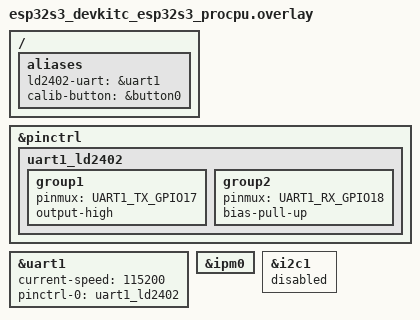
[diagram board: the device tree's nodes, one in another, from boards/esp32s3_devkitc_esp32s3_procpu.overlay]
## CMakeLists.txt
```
# PRO_CPU (core 0) image = sensor core. Sysbuild adds the APP_CPU image (remote/).
cmake_minimum_required(VERSION 3.20.0)

find_package(Zephyr REQUIRED HINTS $ENV{ZEPHYR_BASE})
project(ld2402_sensor_procpu)

target_include_directories(app PRIVATE common src)
target_sources(app PRIVATE
	src/sensor_main.c
	src/ld2402.c
	src/radar_trend.c
	src/radar_filter.c
	common/radar_link_ipm.c
)
```

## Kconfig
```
# Sensor-core application options.
mainmenu "LD2402 sensor core"

config LD2402_RX_POLLING
	bool "Poll the LD2402 UART instead of using RX interrupts"
	help
	  Fallback for a UART whose RX interrupt is not delivered to this core.
	  Default (n) uses UART RX interrupts + a ring buffer.

source "Kconfig.zephyr"
```

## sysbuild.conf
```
# Espressif boards default to MCUboot under sysbuild. SB_CONFIG_BOOTLOADER is
# a Kconfig choice, so the alternative must be selected explicitly with =y.
SB_CONFIG_BOOTLOADER_NONE=y
SB_CONFIG_BOOTLOADER_MCUBOOT=n
```

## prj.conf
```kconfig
# PRO_CPU (core 0) - sensor core: LD2402 on UART1 + IPM tx to APP_CPU

CONFIG_PRINTK=y
CONFIG_SERIAL=y
CONFIG_MAIN_STACK_SIZE=4096

# LD2402 RX path: UART interrupt + ring buffer (see CONFIG_LD2402_RX_POLLING)
CONFIG_UART_INTERRUPT_DRIVEN=y
CONFIG_RING_BUFFER=y

# BOOT button (alias calib-button) for auto threshold calibration
CONFIG_GPIO=y

# Inter-core link. CONFIG_IPM also makes PRO_CPU load and start APP_CPU.
CONFIG_IPM=y
CONFIG_ESP32_SOFT_IPM=y

# log10f() for gate energy -> dB (ESP32-S3 has a hardware FPU)
CONFIG_FPU=y
```

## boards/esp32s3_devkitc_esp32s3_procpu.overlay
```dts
/*
 * PRO_CPU (sensor core) devicetree overlay.
 *
 * LD2402 wiring (3.3 V logic on both sides - no level shifter):
 *   ESP32-S3 GPIO17 (UART1 TX) -> LD2402 R (RX)
 *   ESP32-S3 GPIO18 (UART1 RX) <- LD2402 T (TX)
 *   3V3 -> LD2402 V, GND -> LD2402 G   (LD2402 IO pin unused)
 *
 * calib-button: onboard BOOT button (GPIO0, active low). Hold it 2 s to
 * run the radar's automatic threshold generation (see sensor_main.c).
 *
 * The pin group is defined here with its own label (uart1_ld2402) so the
 * lab does not depend on the board's default uart1_default contents.
 */
#include <dt-bindings/pinctrl/esp32s3-pinctrl.h>

/ {
	aliases {
		ld2402-uart = &uart1;
		calib-button = &button0;
	};
};

&pinctrl {
	uart1_ld2402: uart1_ld2402 {
		group1 {
			pinmux = <UART1_TX_GPIO17>;
			output-high;
		};
		group2 {
			pinmux = <UART1_RX_GPIO18>;
			bias-pull-up;
		};
	};
};

&uart1 {
	status = "okay";
	current-speed = <115200>;
	pinctrl-0 = <&uart1_ld2402>;
	pinctrl-names = "default";
};

&ipm0 {
	status = "okay";
};

/* I2C1 is owned by APP_CPU (display core) - keep it off on this core. */
&i2c1 {
	status = "disabled";
};
```

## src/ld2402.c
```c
/*
 * ld2402.c - minimal HLK-LD2402 24 GHz radar driver.
 *
 * Layers (top to bottom):
 *   public API     : ld2402_read_report(), configuration commands
 *                    (version, engineering mode, parameters, auto threshold)
 *   command layer  : ld2402_command() - send a command frame, wait for its ACK
 *   frame parser   : parser_feed()    - byte-wise state machine, all 3 formats
 *   RX byte source : rx_get_byte()    - UART IRQ + ring buffer, or polling
 *
 * Only the thread that calls the public API consumes RX bytes, so the parser
 * needs no locking. The UART ISR only produces bytes into the ring buffer.
 */
#include "ld2402.h"

#include <errno.h>
#include <math.h>
#include <stdlib.h>
#include <string.h>
#include <zephyr/drivers/uart.h>
#include <zephyr/sys/printk.h>
#include <zephyr/sys/ring_buffer.h>

/* ------------------------------------------------------------------------ */
/* Protocol constants (manual V1.08, chapter 5)                              */
/* ------------------------------------------------------------------------ */

#define DATA_HEADER   0xF4F3F2F1u /* as shifted into a 32-bit window */
#define CMD_HEADER    0xFDFCFBFAu

static const uint8_t DATA_FOOTER[4] = {0xF8, 0xF7, 0xF6, 0xF5};
static const uint8_t CMD_FOOTER[4]  = {0x04, 0x03, 0x02, 0x01};

#define CMD_READ_VERSION   0x0000
#define CMD_WRITE_PARAMS   0x0007
#define CMD_READ_PARAMS    0x0008
#define CMD_AUTO_THRESHOLD 0x0009
#define CMD_AUTO_PROGRESS  0x000A
#define CMD_SET_MODE       0x0012
#define CMD_SAVE_PARAMS    0x00FD
#define CMD_END_CONFIG     0x00FE
#define CMD_ENABLE_CONFIG  0x00FF
#define ACK_BIT            0x0100 /* ACK command word = sent command | 0x0100 */

#define MODE_ENGINEERING   0x00000004u

/* presence(1) + distance(2) + 32 gates x 4 bytes = 131 = 0x83 */
#define ENERGY_FRAME_LEN   (1 + 2 + (2 * LD2402_GATE_COUNT * 4))

#define MAX_PAYLOAD        160
#define MAX_ASCII_LINE     32
#define ACK_TIMEOUT_MS     500
#define SAVE_TIMEOUT_MS    3000  /* flash write takes longer than other commands */

#define PARAM_MAX_DISTANCE     0x0001
#define PARAM_DISAPPEAR_DELAY  0x0004
#define PARAM_POWER_INTERF     0x0005
#define PARAM_MOTION_THR_BASE  0x0010
#define PARAM_MICRO_THR_BASE   0x0030
#define PARAMS_PER_READ        8     /* 8 IDs = 16-byte value, fits the TX frame */

/* ------------------------------------------------------------------------ */
/* Frame parser                                                              */
/* ------------------------------------------------------------------------ */

enum parser_state {
	ST_SYNC,      /* hunting for a binary header or an ASCII line start */
	ST_LEN_LO,
	ST_LEN_HI,
	ST_PAYLOAD,
	ST_FOOTER,
	ST_ASCII,
};

enum frame_kind {
	KIND_DATA,
	KIND_ACK,
};

enum parse_event {
	EVT_NONE,
	EVT_REPORT, /* parser.report holds a new radar report */
	EVT_ACK,    /* parser.ack_* hold a new command ACK */
};

struct parser {
	enum parser_state state;
	enum frame_kind kind;
	uint32_t window;     /* last 4 bytes seen in ST_SYNC */
	uint16_t len;
	uint16_t pos;
	uint8_t footer_pos;
	uint8_t payload[MAX_PAYLOAD];
	char line[MAX_ASCII_LINE];
	uint8_t line_len;

	/* outputs */
	struct ld2402_report report;
	uint16_t ack_word;
	uint16_t ack_status;
	const uint8_t *ack_data; /* points into payload[] */
	uint16_t ack_data_len;
};

static struct parser s_parser;
static struct ld2402_stats s_stats;

static uint16_t get_le16(const uint8_t *p)
{
	return (uint16_t)(p[0] | (p[1] << 8));
}

static uint32_t get_le32(const uint8_t *p)
{
	return (uint32_t)p[0] | ((uint32_t)p[1] << 8) |
	       ((uint32_t)p[2] << 16) | ((uint32_t)p[3] << 24);
}

static void parser_reset(struct parser *p)
{
	p->state = ST_SYNC;
	p->window = 0;
	p->line_len = 0;
}

/* "OFF" or "distance:123" (normal working mode, manual 5.6.1) */
static bool parse_ascii_line(struct parser *p)
{
	static const char prefix[] = "distance:";
	struct ld2402_report *r = &p->report;

	if (strcmp(p->line, "OFF") == 0) {
		memset(r, 0, sizeof(*r));
		r->presence = LD2402_PRESENCE_NONE;
		return true;
	}

	if (strncmp(p->line, prefix, sizeof(prefix) - 1) == 0) {
		memset(r, 0, sizeof(*r));
		r->presence = LD2402_PRESENCE_MOVING;
		r->distance_cm = (uint16_t)strtoul(p->line + sizeof(prefix) - 1, NULL, 10);
		return true;
	}

	return false;
}

/* Engineering frame payload: presence(1) distance(2) [motion x16][micro x16] */
static bool decode_data_frame(struct parser *p)
{
	struct ld2402_report *r = &p->report;

	if (p->len < 3) {
		return false;
	}

	memset(r, 0, sizeof(*r));
	r->presence = p->payload[0];
	r->distance_cm = get_le16(&p->payload[1]);

	if (p->len >= ENERGY_FRAME_LEN) {
		const uint8_t *e = &p->payload[3];

		for (int i = 0; i < LD2402_GATE_COUNT; i++) {
			r->motion_energy[i] = get_le32(e + (i * 4));
			r->micro_energy[i] = get_le32(e + ((LD2402_GATE_COUNT + i) * 4));
		}
		r->has_energy = true;
	}

	return true;
}

/* ACK payload: ack_word(2) status(2) data(N) */
static bool decode_ack_frame(struct parser *p)
{
	if (p->len < 4) {
		return false;
	}

	p->ack_word = get_le16(&p->payload[0]);
	p->ack_status = get_le16(&p->payload[2]);
	p->ack_data = &p->payload[4];
	p->ack_data_len = p->len - 4;
	return true;
}

static enum parse_event parser_feed(struct parser *p, uint8_t b)
{
	switch (p->state) {
	case ST_SYNC:
		p->window = (p->window << 8) | b;

		if (p->window == DATA_HEADER || p->window == CMD_HEADER) {
			p->kind = (p->window == DATA_HEADER) ? KIND_DATA : KIND_ACK;
			p->window = 0;
			p->state = ST_LEN_LO;
		} else if (b == 'O' || b == 'd') {
			/* start of "OFF" or "distance:" */
			p->line[0] = (char)b;
			p->line_len = 1;
			p->state = ST_ASCII;
		}
		break;

	case ST_ASCII:
		if (b == '\r' || b == '\n') {
			p->line[p->line_len] = '\0';
			parser_reset(p);
			if (parse_ascii_line(p)) {
				s_stats.ascii_lines++;
				return EVT_REPORT;
			}
		} else if (b >= 0x20 && b < 0x7F && p->line_len < (MAX_ASCII_LINE - 1)) {
			p->line[p->line_len++] = (char)b;
		} else {
			/* not a text line after all - keep the byte for header hunting */
			parser_reset(p);
			p->window = b;
		}
		break;

	case ST_LEN_LO:
		p->len = b;
		p->state = ST_LEN_HI;
		break;

	case ST_LEN_HI:
		p->len |= (uint16_t)(b << 8);
		if (p->len == 0 || p->len > MAX_PAYLOAD) {
			s_stats.bad_frames++;
			parser_reset(p);
		} else {
			p->pos = 0;
			p->state = ST_PAYLOAD;
		}
		break;

	case ST_PAYLOAD:
		p->payload[p->pos++] = b;
		if (p->pos == p->len) {
			p->footer_pos = 0;
			p->state = ST_FOOTER;
		}
		break;

	case ST_FOOTER: {
		const uint8_t *footer = (p->kind == KIND_DATA) ? DATA_FOOTER : CMD_FOOTER;

		if (b != footer[p->footer_pos]) {
			s_stats.bad_frames++;
			parser_reset(p);
			p->window = b;
			break;
		}

		if (++p->footer_pos < sizeof(DATA_FOOTER)) {
			break;
		}

		parser_reset(p);
		if (p->kind == KIND_DATA) {
			if (decode_data_frame(p)) {
				s_stats.binary_frames++;
				return EVT_REPORT;
			}
		} else {
			if (decode_ack_frame(p)) {
				return EVT_ACK;
			}
		}
		s_stats.bad_frames++;
		break;
	}
	}

	return EVT_NONE;
}

/* ------------------------------------------------------------------------ */
/* RX byte source                                                            */
/* ------------------------------------------------------------------------ */

static const struct device *s_uart;

#ifndef CONFIG_LD2402_RX_POLLING

#define RX_RING_SIZE 512

RING_BUF_DECLARE(s_rx_ring, RX_RING_SIZE);
K_SEM_DEFINE(s_rx_sem, 0, 1);

static void uart_isr(const struct device *dev, void *user_data)
{
	ARG_UNUSED(user_data);

	/*
	 * Return type differs across Zephyr versions (int in older releases,
	 * void in newer ones), so call it as a statement and never test it.
	 */
	uart_irq_update(dev);

	while (uart_irq_rx_ready(dev)) {
		uint8_t chunk[32];
		int n = uart_fifo_read(dev, chunk, sizeof(chunk));

		if (n <= 0) {
			break;
		}
		if (ring_buf_put(&s_rx_ring, chunk, n) < (uint32_t)n) {
			s_stats.rx_overflows++;
		}
		k_sem_give(&s_rx_sem);
	}
}

static int rx_start(void)
{
	int ret = uart_irq_callback_user_data_set(s_uart, uart_isr, NULL);

	if (ret != 0) {
		return ret;
	}
	uart_irq_rx_enable(s_uart);
	return 0;
}

static int rx_get_byte(uint8_t *b, k_timepoint_t end)
{
	while (ring_buf_get(&s_rx_ring, b, 1) == 0) {
		if (k_sem_take(&s_rx_sem, sys_timepoint_timeout(end)) != 0) {
			return -EAGAIN;
		}
	}
	return 0;
}

static void rx_drain(void)
{
	uint8_t junk[32];

	while (ring_buf_get(&s_rx_ring, junk, sizeof(junk)) > 0) {
	}
}

#else /* CONFIG_LD2402_RX_POLLING */

static int rx_start(void)
{
	return 0;
}

static int rx_get_byte(uint8_t *b, k_timepoint_t end)
{
	while (uart_poll_in(s_uart, b) != 0) {
		if (sys_timepoint_expired(end)) {
			return -EAGAIN;
		}
		/* 1 ms at 115200 bps = ~11.5 bytes, below the 16-byte HW FIFO */
		k_sleep(K_MSEC(1));
	}
	return 0;
}

static void rx_drain(void)
{
	uint8_t junk;

	while (uart_poll_in(s_uart, &junk) == 0) {
	}
}

#endif /* CONFIG_LD2402_RX_POLLING */

/* ------------------------------------------------------------------------ */
/* Command layer                                                             */
/* ------------------------------------------------------------------------ */

/* FD FC FB FA | len(2) | cmd(2) value(N) | 04 03 02 01 */
static size_t build_cmd_frame(uint8_t *buf, uint16_t cmd,
			      const uint8_t *value, uint16_t value_len)
{
	uint16_t inner_len = 2 + value_len;
	size_t n = 0;

	buf[n++] = 0xFD;
	buf[n++] = 0xFC;
	buf[n++] = 0xFB;
	buf[n++] = 0xFA;
	buf[n++] = (uint8_t)(inner_len & 0xFF);
	buf[n++] = (uint8_t)(inner_len >> 8);
	buf[n++] = (uint8_t)(cmd & 0xFF);
	buf[n++] = (uint8_t)(cmd >> 8);
	if (value_len > 0) {
		memcpy(&buf[n], value, value_len);
		n += value_len;
	}
	memcpy(&buf[n], CMD_FOOTER, sizeof(CMD_FOOTER));
	n += sizeof(CMD_FOOTER);

	return n;
}

/*
 * Send one command and wait for the matching ACK. Radar data frames that
 * arrive in the meantime are parsed and silently dropped.
 * On success, s_parser.ack_data/ack_data_len point at the ACK return data.
 */
static int ld2402_command(uint16_t cmd, const uint8_t *value, uint16_t value_len,
			  uint32_t timeout_ms)
{
	uint8_t frame[32];
	size_t frame_len;
	k_timepoint_t end;

	if (value_len > sizeof(frame) - 12) {
		return -EINVAL;
	}

	frame_len = build_cmd_frame(frame, cmd, value, value_len);

	rx_drain();
	parser_reset(&s_parser);

	for (size_t i = 0; i < frame_len; i++) {
		uart_poll_out(s_uart, frame[i]);
	}

	end = sys_timepoint_calc(K_MSEC(timeout_ms));

	while (true) {
		uint8_t b;

		if (rx_get_byte(&b, end) != 0) {
			return -ETIMEDOUT;
		}
		if (parser_feed(&s_parser, b) != EVT_ACK) {
			continue;
		}
		if (s_parser.ack_word != (cmd | ACK_BIT)) {
			continue; /* stale ACK of a previous command */
		}
		return (s_parser.ack_status == 0) ? 0 : -EIO;
	}
}

static void put_le16(uint8_t *p, uint16_t v)
{
	p[0] = (uint8_t)(v & 0xFF);
	p[1] = (uint8_t)(v >> 8);
}

static void put_le32(uint8_t *p, uint32_t v)
{
	p[0] = (uint8_t)(v & 0xFF);
	p[1] = (uint8_t)((v >> 8) & 0xFF);
	p[2] = (uint8_t)((v >> 16) & 0xFF);
	p[3] = (uint8_t)((v >> 24) & 0xFF);
}

/* 0x0008: value = ID(2) x n, ACK data = value(4) x n (same order) */
static int read_param_batch(uint16_t first_id, int count, uint32_t *out)
{
	uint8_t value[PARAMS_PER_READ * 2];
	int ret;

	if (count > PARAMS_PER_READ) {
		return -EINVAL;
	}
	for (int i = 0; i < count; i++) {
		put_le16(&value[i * 2], (uint16_t)(first_id + i));
	}

	ret = ld2402_command(CMD_READ_PARAMS, value, (uint16_t)(count * 2), ACK_TIMEOUT_MS);
	if (ret != 0) {
		return ret;
	}
	if (s_parser.ack_data_len < count * 4) {
		return -EBADMSG;
	}
	for (int i = 0; i < count; i++) {
		out[i] = get_le32(s_parser.ack_data + (i * 4));
	}
	return 0;
}

/* 0x0007: value = (ID(2) + value(4)) x n - this lab writes one at a time */
static int write_param(uint16_t id, uint32_t param_value)
{
	uint8_t value[6];

	put_le16(&value[0], id);
	put_le32(&value[2], param_value);
	return ld2402_command(CMD_WRITE_PARAMS, value, sizeof(value), ACK_TIMEOUT_MS);
}

/* ------------------------------------------------------------------------ */
/* Configuration commands (public, call between config_begin/config_end)     */
/* ------------------------------------------------------------------------ */

int ld2402_config_begin(void)
{
	static const uint8_t value[] = {0x01, 0x00};

	return ld2402_command(CMD_ENABLE_CONFIG, value, sizeof(value), ACK_TIMEOUT_MS);
}

int ld2402_config_end(void)
{
	return ld2402_command(CMD_END_CONFIG, NULL, 0, ACK_TIMEOUT_MS);
}

/* ACK data: version_len(2) + version string (e.g. "v3.5.5") */
int ld2402_read_version(char *out, size_t out_len)
{
	int ret = ld2402_command(CMD_READ_VERSION, NULL, 0, ACK_TIMEOUT_MS);
	uint16_t ver_len;

	if (ret != 0) {
		return ret;
	}
	if (s_parser.ack_data_len < 2 || out_len < 2) {
		return -EBADMSG;
	}

	ver_len = get_le16(s_parser.ack_data);
	ver_len = MIN(ver_len, (uint16_t)(s_parser.ack_data_len - 2));
	ver_len = MIN(ver_len, (uint16_t)(out_len - 1));

	memcpy(out, s_parser.ack_data + 2, ver_len);
	out[ver_len] = '\0';
	return 0;
}

/* 0x0012: value = 0x0000 (2 bytes) + mode (4 bytes) */
int ld2402_set_engineering_mode(void)
{
	uint8_t value[6];

	put_le16(&value[0], 0x0000);
	put_le32(&value[2], MODE_ENGINEERING);
	return ld2402_command(CMD_SET_MODE, value, sizeof(value), ACK_TIMEOUT_MS);
}

int ld2402_read_params(struct ld2402_params *out)
{
	uint32_t basic[1];
	int ret;

	memset(out, 0, sizeof(*out));

	/* IDs 0x0001 / 0x0004 / 0x0005 are not contiguous - read one by one */
	ret = read_param_batch(PARAM_MAX_DISTANCE, 1, basic);
	if (ret != 0) {
		return ret;
	}
	out->max_distance = basic[0];

	ret = read_param_batch(PARAM_DISAPPEAR_DELAY, 1, basic);
	if (ret != 0) {
		return ret;
	}
	out->disappear_delay_s = basic[0];

	/* read-only status; older firmware may not know it - not fatal */
	if (read_param_batch(PARAM_POWER_INTERF, 1, basic) == 0) {
		out->power_interference = basic[0];
	}

	for (int i = 0; i < LD2402_GATE_COUNT; i += PARAMS_PER_READ) {
		ret = read_param_batch((uint16_t)(PARAM_MOTION_THR_BASE + i), PARAMS_PER_READ,
				       &out->motion_threshold[i]);
		if (ret != 0) {
			return ret;
		}
		ret = read_param_batch((uint16_t)(PARAM_MICRO_THR_BASE + i), PARAMS_PER_READ,
				       &out->micro_threshold[i]);
		if (ret != 0) {
			return ret;
		}
	}
	return 0;
}

/* 0x0009: value = trigger(2) hold(2) micro(2), each coefficient x10 */
int ld2402_auto_threshold_start(uint16_t trigger_x10, uint16_t hold_x10, uint16_t micro_x10)
{
	uint8_t value[6];

	put_le16(&value[0], trigger_x10);
	put_le16(&value[2], hold_x10);
	put_le16(&value[4], micro_x10);
	return ld2402_command(CMD_AUTO_THRESHOLD, value, sizeof(value), ACK_TIMEOUT_MS);
}

/* 0x000A: ACK data = progress(2), 0..100 */
int ld2402_auto_threshold_progress(uint8_t *percent)
{
	int ret = ld2402_command(CMD_AUTO_PROGRESS, NULL, 0, ACK_TIMEOUT_MS);
	uint16_t progress;

	if (ret != 0) {
		return ret;
	}
	if (s_parser.ack_data_len < 2) {
		return -EBADMSG;
	}
	progress = get_le16(s_parser.ack_data);
	*percent = (uint8_t)MIN(progress, 100);
	return 0;
}

/*
 * 0x00FD exists from FW 3.3.2. Older firmware saves to flash when parameter
 * 0x003F is written (manual 5.2.7), so the fallback rewrites its own value.
 */
int ld2402_save_params(void)
{
	uint32_t micro_last;
	int ret;

	ret = ld2402_command(CMD_SAVE_PARAMS, NULL, 0, SAVE_TIMEOUT_MS);
	if (ret == 0) {
		return 0;
	}

	ret = read_param_batch(PARAM_MICRO_THR_BASE + LD2402_GATE_COUNT - 1, 1, &micro_last);
	if (ret != 0) {
		return ret;
	}
	return write_param(PARAM_MICRO_THR_BASE + LD2402_GATE_COUNT - 1, micro_last);
}

/* ------------------------------------------------------------------------ */
/* Public API                                                                */
/* ------------------------------------------------------------------------ */

int ld2402_init(const struct device *uart)
{
	if (!device_is_ready(uart)) {
		return -ENODEV;
	}

	s_uart = uart;
	parser_reset(&s_parser);
	memset(&s_stats, 0, sizeof(s_stats));

	return rx_start();
}

int ld2402_read_report(struct ld2402_report *out, k_timeout_t timeout)
{
	k_timepoint_t end = sys_timepoint_calc(timeout);

	while (true) {
		uint8_t b;
		int ret = rx_get_byte(&b, end);

		if (ret != 0) {
			return ret;
		}
		if (parser_feed(&s_parser, b) == EVT_REPORT) {
			*out = s_parser.report;
			return 0;
		}
	}
}

uint8_t ld2402_energy_to_db(uint32_t raw)
{
	if (raw == 0) {
		return 0;
	}
	/* max: 10 * log10(2^32 - 1) = 96.3 dB -> fits in uint8_t */
	return (uint8_t)lroundf(10.0f * log10f((float)raw));
}

void ld2402_get_stats(struct ld2402_stats *out)
{
	*out = s_stats;
}
```

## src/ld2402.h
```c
/*
 * ld2402.h - minimal HLK-LD2402 24 GHz radar driver (UART, 115200 8N1).
 *
 * Protocol reference: Hi-Link "HLK-LD2402 User Manual" V1.08, chapter 5.
 *
 * Supported input formats (auto-detected, can be mixed on the wire):
 *   1. Normal mode   : ASCII lines "OFF\r\n" / "distance:123\r\n"
 *   2. Engineering   : binary frame
 *        F4 F3 F2 F1 | len(2) | presence(1) distance(2) energy(32 x 4) | F8 F7 F6 F5
 *   3. Command ACK   : binary frame
 *        FD FC FB FA | len(2) | cmd|0x0100 (2) status(2) data(N)    | 04 03 02 01
 *
 * Single-instance driver on purpose (one radar per board in this lab).
 */
#ifndef LD2402_H_
#define LD2402_H_

#include <stdbool.h>
#include <stddef.h>
#include <stdint.h>
#include <zephyr/device.h>
#include <zephyr/kernel.h>

#define LD2402_GATE_COUNT    16
#define LD2402_GATE_SIZE_CM  70

enum ld2402_presence {
	LD2402_PRESENCE_NONE   = 0,
	LD2402_PRESENCE_MOVING = 1, /* normal (ASCII) mode always reports this when present */
	LD2402_PRESENCE_STILL  = 2, /* only distinguishable in engineering mode */
};

struct ld2402_report {
	uint8_t  presence;     /* enum ld2402_presence */
	uint16_t distance_cm;
	bool     has_energy;   /* true only for engineering-mode frames */
	uint32_t motion_energy[LD2402_GATE_COUNT]; /* raw linear energy */
	uint32_t micro_energy[LD2402_GATE_COUNT];  /* raw linear energy */
};

struct ld2402_stats {
	uint32_t binary_frames;  /* engineering frames decoded */
	uint32_t ascii_lines;    /* normal-mode lines decoded */
	uint32_t bad_frames;     /* length/footer errors */
	uint32_t rx_overflows;   /* ring buffer full (IRQ mode only) */
};

struct ld2402_params {
	uint32_t max_distance;        /* 0x0001, 0.1 m units (7..100) */
	uint32_t disappear_delay_s;   /* 0x0004, seconds */
	uint32_t power_interference;  /* 0x0005, 0 = not checked, 1 = none, 2 = detected */
	uint32_t motion_threshold[LD2402_GATE_COUNT]; /* 0x0010..0x001F, linear */
	uint32_t micro_threshold[LD2402_GATE_COUNT];  /* 0x0030..0x003F, linear */
};

/* Bind the driver to an already-configured UART (115200 8N1) and start RX. */
int ld2402_init(const struct device *uart);

/*
 * Configuration session. Every command below must be issued between
 * ld2402_config_begin() and ld2402_config_end(); the radar stops reporting
 * while it is in configuration mode.
 */
int ld2402_config_begin(void);
int ld2402_config_end(void);

int ld2402_read_version(char *out, size_t out_len);
int ld2402_set_engineering_mode(void);
int ld2402_read_params(struct ld2402_params *out);

/*
 * Automatic threshold generation (manual 5.2.9 / 5.2.10). The detection area
 * must be empty while it runs. Coefficients are x10 (30 = 3.0, range 10..200).
 */
int ld2402_auto_threshold_start(uint16_t trigger_x10, uint16_t hold_x10, uint16_t micro_x10);
int ld2402_auto_threshold_progress(uint8_t *percent);

/* Persist parameters to the radar's flash (0x00FD, fallback: rewrite 0x003F). */
int ld2402_save_params(void);

/* Block until the next radar report arrives or the timeout expires (-EAGAIN). */
int ld2402_read_report(struct ld2402_report *out, k_timeout_t timeout);

/* Convert a raw energy value to dB as defined by the manual: 10 * log10(raw). */
uint8_t ld2402_energy_to_db(uint32_t raw);

void ld2402_get_stats(struct ld2402_stats *out);

#endif /* LD2402_H_ */
```

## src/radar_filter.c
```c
/*
 * radar_filter.c - sliding median filter (see radar_filter.h).
 */
#include "radar_filter.h"

#include <string.h>

void radar_median_reset(struct radar_median *f)
{
	memset(f, 0, sizeof(*f));
}

uint16_t radar_median_update(struct radar_median *f, uint16_t sample)
{
	uint16_t sorted[RADAR_MEDIAN_WINDOW];

	f->samples[f->head] = sample;
	f->head = (uint8_t)((f->head + 1) % RADAR_MEDIAN_WINDOW);
	if (f->count < RADAR_MEDIAN_WINDOW) {
		f->count++;
	}

	/* insertion sort of at most 5 values - order of the ring does not matter */
	memcpy(sorted, f->samples, f->count * sizeof(sorted[0]));
	for (int i = 1; i < f->count; i++) {
		uint16_t key = sorted[i];
		int j = i - 1;

		while (j >= 0 && sorted[j] > key) {
			sorted[j + 1] = sorted[j];
			j--;
		}
		sorted[j + 1] = key;
	}

	return sorted[f->count / 2];
}
```

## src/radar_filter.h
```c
/*
 * radar_filter.h - sliding median filter for the LD2402 distance.
 *
 * A median (not a mean) rejects single-frame spikes - e.g. one frame that
 * locks onto a wall reflection - without smearing them into the result.
 * Window 5 = ~0.8 s of history at 165 ms/frame, adds ~2 frames of lag.
 */
#ifndef RADAR_FILTER_H_
#define RADAR_FILTER_H_

#include <stdint.h>

#define RADAR_MEDIAN_WINDOW  5

struct radar_median {
	uint16_t samples[RADAR_MEDIAN_WINDOW];
	uint8_t  head;
	uint8_t  count;
};

void radar_median_reset(struct radar_median *f);

/* Add one sample and return the median of the samples in the window. */
uint16_t radar_median_update(struct radar_median *f, uint16_t sample);

#endif /* RADAR_FILTER_H_ */
```

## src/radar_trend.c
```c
/*
 * radar_trend.c - approach / leave detection (see radar_trend.h).
 */
#include "radar_trend.h"

#include <stdlib.h>
#include <string.h>

#include "radar_msg.h"

void radar_trend_reset(struct radar_trend *tr)
{
	memset(tr, 0, sizeof(*tr));
	tr->direction = RADAR_DIR_UNKNOWN;
}

static uint8_t newest_index(const struct radar_trend *tr)
{
	return (uint8_t)((tr->head + RADAR_TREND_WINDOW - 1) % RADAR_TREND_WINDOW);
}

/* Least-squares slope of distance over time, in cm/s. */
static int32_t estimate_speed_cms(const struct radar_trend *tr)
{
	uint8_t oldest = (uint8_t)((tr->head + RADAR_TREND_WINDOW - tr->count) % RADAR_TREND_WINDOW);
	int64_t t0 = tr->t_ms[oldest];
	int64_t n = tr->count;
	int64_t sum_x = 0, sum_y = 0, sum_xy = 0, sum_xx = 0;
	int64_t denom;

	for (uint8_t i = 0; i < tr->count; i++) {
		uint8_t idx = (uint8_t)((oldest + i) % RADAR_TREND_WINDOW);
		int64_t x = tr->t_ms[idx] - t0; /* ms */
		int64_t y = tr->dist_cm[idx];   /* cm */

		sum_x += x;
		sum_y += y;
		sum_xy += x * y;
		sum_xx += x * x;
	}

	denom = (n * sum_xx) - (sum_x * sum_x);
	if (denom == 0) {
		return 0;
	}

	/* slope [cm/ms] * 1000 = [cm/s] */
	return (int32_t)((((n * sum_xy) - (sum_x * sum_y)) * 1000) / denom);
}

static uint8_t classify(uint8_t current, int32_t speed)
{
	switch (current) {
	case RADAR_DIR_APPROACH:
		if (speed < -RADAR_TREND_EXIT_CMS) {
			return RADAR_DIR_APPROACH;
		}
		break;
	case RADAR_DIR_LEAVE:
		if (speed > RADAR_TREND_EXIT_CMS) {
			return RADAR_DIR_LEAVE;
		}
		break;
	default:
		break;
	}

	if (speed <= -RADAR_TREND_ENTER_CMS) {
		return RADAR_DIR_APPROACH;
	}
	if (speed >= RADAR_TREND_ENTER_CMS) {
		return RADAR_DIR_LEAVE;
	}
	return RADAR_DIR_STEADY;
}

/* Debounce: switch only after the same candidate was seen CONFIRM times. */
static void confirm_direction(struct radar_trend *tr, uint8_t candidate)
{
	if (candidate == tr->direction) {
		tr->pending_count = 0;
		return;
	}
	if (tr->direction == RADAR_DIR_UNKNOWN) {
		tr->direction = candidate; /* first decision after (re)start */
		tr->pending_count = 0;
		return;
	}
	if (candidate != tr->pending) {
		tr->pending = candidate;
		tr->pending_count = 0;
	}
	if (++tr->pending_count >= RADAR_TREND_CONFIRM) {
		tr->direction = candidate;
		tr->pending_count = 0;
	}
}

void radar_trend_update(struct radar_trend *tr, int64_t now_ms,
			uint16_t distance_cm, bool present)
{
	int32_t speed;

	if (!present) {
		radar_trend_reset(tr);
		return;
	}

	if (tr->count > 0) {
		uint8_t last = newest_index(tr);
		bool gap = (now_ms - tr->t_ms[last]) > RADAR_TREND_MAX_GAP_MS;
		bool jump = abs((int)distance_cm - (int)tr->dist_cm[last]) > RADAR_TREND_JUMP_CM;

		if (gap || jump) {
			radar_trend_reset(tr);
		}
	}

	tr->t_ms[tr->head] = now_ms;
	tr->dist_cm[tr->head] = distance_cm;
	tr->head = (uint8_t)((tr->head + 1) % RADAR_TREND_WINDOW);
	if (tr->count < RADAR_TREND_WINDOW) {
		tr->count++;
	}

	if (tr->count < RADAR_TREND_MIN_SAMPLES) {
		tr->direction = RADAR_DIR_UNKNOWN;
		tr->pending_count = 0;
		tr->speed_cms = 0;
		return;
	}

	speed = estimate_speed_cms(tr);
	tr->speed_cms = (int16_t)speed;
	confirm_direction(tr, classify(tr->direction, speed));
}
```

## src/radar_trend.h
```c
/*
 * radar_trend.h - approach / leave detection from the LD2402 distance stream.
 *
 * The LD2402 is a 1T1R radar: it reports radial distance only (no angle, no
 * speed). The radial speed is estimated here as the least-squares slope of
 * the last few distance samples, then classified with hysteresis:
 *
 *   speed <= -ENTER  -> APPROACH      (stays until speed > -EXIT)
 *   speed >= +ENTER  -> LEAVE         (stays until speed < +EXIT)
 *   otherwise        -> STEADY
 *
 * A new direction must be seen on RADAR_TREND_CONFIRM consecutive updates
 * before it is reported (debounce against +-15 cm distance noise).
 *
 * The window is reset when the target disappears, when frames stop for a
 * while, or when the distance jumps (most likely a different target).
 */
#ifndef RADAR_TREND_H_
#define RADAR_TREND_H_

#include <stdbool.h>
#include <stdint.h>

#define RADAR_TREND_WINDOW       8    /* samples, ~1.3 s at 165 ms/frame */
#define RADAR_TREND_MIN_SAMPLES  5    /* need ~0.8 s of data before deciding */
#define RADAR_TREND_MAX_GAP_MS   600  /* frame gap that invalidates the window */
#define RADAR_TREND_JUMP_CM      100  /* single-step jump treated as target switch */
#define RADAR_TREND_ENTER_CMS    20   /* |speed| to enter APPROACH/LEAVE */
#define RADAR_TREND_EXIT_CMS     10   /* |speed| below which we fall back to STEADY */
#define RADAR_TREND_CONFIRM      3    /* consecutive updates needed to change direction */

struct radar_trend {
	int64_t  t_ms[RADAR_TREND_WINDOW];
	uint16_t dist_cm[RADAR_TREND_WINDOW];
	uint8_t  head;      /* next write index */
	uint8_t  count;     /* valid samples in the window */
	uint8_t  direction; /* enum radar_direction (reported, debounced) */
	uint8_t  pending;   /* candidate direction waiting for confirmation */
	uint8_t  pending_count;
	int16_t  speed_cms; /* last estimated radial speed */
};

void radar_trend_reset(struct radar_trend *tr);

/* Feed one radar report. 'present' = target detected in this report. */
void radar_trend_update(struct radar_trend *tr, int64_t now_ms,
			uint16_t distance_cm, bool present);

#endif /* RADAR_TREND_H_ */
```

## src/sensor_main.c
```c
/*
 * sensor_main.c - sensor core application (identical on ESP32-S3 and SR110).
 *
 *   ESP32-S3 : runs on PRO_CPU (core 0)
 *   SR110    : runs on Cortex-M4 (Always-On core)
 *
 * Flow:
 *   1. Bind the LD2402 driver to the UART selected by alias "ld2402-uart".
 *   2. Startup config session: firmware version, dump of the current radar
 *      parameters (max distance, disappear delay, per-gate thresholds),
 *      switch to engineering mode. Retries, falls back to ASCII mode.
 *   3. Loop: read radar reports, median-filter the distance, estimate
 *      approach/leave (radar_trend), push radar_msg to the display core on
 *      change or periodically (heartbeat).
 *   4. Optional (devicetree alias "calib-button"): long press runs the
 *      radar's automatic threshold generation and saves it to radar flash,
 *      with countdown/progress shown on the display core.
 */
#include <errno.h>
#include <stdlib.h>
#include <string.h>
#include <zephyr/device.h>
#include <zephyr/devicetree.h>
#include <zephyr/drivers/gpio.h>
#include <zephyr/kernel.h>
#include <zephyr/sys/printk.h>

#include "ld2402.h"
#include "radar_filter.h"
#include "radar_link.h"
#include "radar_msg.h"
#include "radar_trend.h"

#define LD2402_UART_NODE     DT_ALIAS(ld2402_uart)
#define CALIB_BUTTON_NODE    DT_ALIAS(calib_button)
#define HAS_CALIB_BUTTON     DT_NODE_EXISTS(CALIB_BUTTON_NODE)

#define STARTUP_RETRIES      5
#define STARTUP_RETRY_MS     1000
#define REPORT_WAIT_MS       500   /* loop tick while the radar is silent */
#define SENSOR_TIMEOUT_MS    2000  /* no report this long -> SENSOR_OK cleared */
#define DIST_DELTA_CM        10    /* distance change that triggers an immediate send */
#define PERIODIC_SEND_MS     500   /* bar-graph refresh + heartbeat */
#define LOG_PERIOD_MS        1000

/* auto threshold generation */
#define CALIB_LONG_PRESS_MS  2000
#define CALIB_COUNTDOWN_S    10    /* time to leave the detection area */
#define CALIB_COEFF_X10      30    /* trigger / hold / micro coefficient 3.0 (tool default) */
#define CALIB_POLL_MS        1000
#define CALIB_TIMEOUT_MS     120000
#define CALIB_RESULT_SHOW_MS 3000

static const struct device *const radar_uart = DEVICE_DT_GET(LD2402_UART_NODE);

#if HAS_CALIB_BUTTON
static const struct gpio_dt_spec calib_button = GPIO_DT_SPEC_GET(CALIB_BUTTON_NODE, gpios);
#endif

static uint32_t tx_seq;

/* ------------------------------------------------------------------------ */
/* Helpers                                                                   */
/* ------------------------------------------------------------------------ */

static const char *presence_name(uint8_t presence)
{
	switch (presence) {
	case RADAR_PRESENCE_MOVING:
		return "MOVE";
	case RADAR_PRESENCE_STILL:
		return "STILL";
	default:
		return "NONE";
	}
}

static const char *direction_name(uint8_t direction)
{
	switch (direction) {
	case RADAR_DIR_APPROACH:
		return "APPROACH";
	case RADAR_DIR_LEAVE:
		return "LEAVE";
	case RADAR_DIR_STEADY:
		return "STEADY";
	default:
		return "-";
	}
}

static int send_msg(struct radar_msg *msg)
{
	msg->seq = ++tx_seq;
	return radar_link_send(msg);
}

/* ------------------------------------------------------------------------ */
/* Radar parameters                                                          */
/* ------------------------------------------------------------------------ */

static void print_gate_row(const char *label, const uint32_t thr[LD2402_GATE_COUNT])
{
	printk("[PARAM] %-9s:", label);
	for (int i = 0; i < LD2402_GATE_COUNT; i++) {
		if (thr == NULL) {
			printk(" %2d", i);
		} else {
			printk(" %2u", (unsigned int)ld2402_energy_to_db(thr[i]));
		}
	}
	printk("\n");
}

static void print_params(const struct ld2402_params *p)
{
	static const char *const interference[] = {"not checked", "none", "DETECTED"};
	uint32_t pi = p->power_interference;

	printk("[PARAM] max distance      : %u.%u m (raw %u)\n",
	       p->max_distance / 10, p->max_distance % 10, p->max_distance);
	printk("[PARAM] disappear delay   : %u s\n", p->disappear_delay_s);
	printk("[PARAM] power interference: %s\n", (pi < 3) ? interference[pi] : "?");
	print_gate_row("gate", NULL);
	print_gate_row("motion dB", p->motion_threshold);
	print_gate_row("micro dB", p->micro_threshold);
	printk("[PARAM] gate n = %d*n .. %d*(n+1) cm; threshold dB = 10*log10(raw)\n",
	       LD2402_GATE_SIZE_CM, LD2402_GATE_SIZE_CM);
}

/* One config session: version -> parameter dump -> engineering mode. */
static int configure_radar(void)
{
	struct ld2402_params params;
	char fw[16] = "unknown";
	int ret;
	int end_ret;

	ret = ld2402_config_begin();
	if (ret != 0) {
		return ret;
	}

	(void)ld2402_read_version(fw, sizeof(fw));
	printk("[SENSOR] LD2402 firmware %s\n", fw);

	if (ld2402_read_params(&params) == 0) {
		print_params(&params);
	} else {
		printk("[PARAM] parameter read failed\n");
	}

	ret = ld2402_set_engineering_mode();

	/* always leave config mode, otherwise the radar stops reporting */
	end_ret = ld2402_config_end();
	return (ret != 0) ? ret : end_ret;
}

static bool start_radar(void)
{
	for (int attempt = 1; attempt <= STARTUP_RETRIES; attempt++) {
		int ret = configure_radar();

		if (ret == 0) {
			printk("[SENSOR] engineering mode ON\n");
			return true;
		}
		printk("[SENSOR] config attempt %d/%d failed (%d)\n", attempt, STARTUP_RETRIES, ret);
		k_msleep(STARTUP_RETRY_MS);
	}

	printk("[SENSOR] falling back to normal (ASCII) mode - no gate energy\n");
	return false;
}

/* ------------------------------------------------------------------------ */
/* Auto threshold calibration (long press on calib-button)                   */
/* ------------------------------------------------------------------------ */

static void send_calib_status(uint8_t state, uint8_t value)
{
	struct radar_msg msg;

	memset(&msg, 0, sizeof(msg));
	msg.magic = RADAR_MSG_MAGIC;
	msg.uptime_ms = k_uptime_get_32();
	msg.flags = RADAR_FLAG_SENSOR_OK;
	msg.calib_state = state;
	msg.calib_pct = value;
	(void)send_msg(&msg);
}

/* Blocking: ~10 s countdown + generation time. Radar reports pause meanwhile. */
static bool run_auto_threshold(void)
{
	struct ld2402_params params;
	int64_t deadline;
	uint8_t percent = 0;
	int ret;

	for (int s = CALIB_COUNTDOWN_S; s > 0; s--) {
		printk("[CALIB] leave the detection area: %d s\n", s);
		send_calib_status(RADAR_CALIB_COUNTDOWN, (uint8_t)s);
		k_msleep(1000);
	}

	ret = ld2402_config_begin();
	if (ret != 0) {
		printk("[CALIB] config begin failed (%d)\n", ret);
		return false;
	}

	ret = ld2402_auto_threshold_start(CALIB_COEFF_X10, CALIB_COEFF_X10, CALIB_COEFF_X10);
	if (ret != 0) {
		printk("[CALIB] start failed (%d)\n", ret);
		goto out_end_config;
	}
	printk("[CALIB] started (coefficients %d.%d)\n", CALIB_COEFF_X10 / 10, CALIB_COEFF_X10 % 10);

	deadline = k_uptime_get() + CALIB_TIMEOUT_MS;
	while (percent < 100) {
		k_msleep(CALIB_POLL_MS);

		if (ld2402_auto_threshold_progress(&percent) == 0) {
			printk("[CALIB] progress %u%%\n", percent);
			send_calib_status(RADAR_CALIB_RUNNING, percent);
		}
		if (k_uptime_get() > deadline) {
			printk("[CALIB] timeout\n");
			ret = -ETIMEDOUT;
			goto out_end_config;
		}
	}

	ret = ld2402_save_params();
	printk("[CALIB] save to radar flash: %s (%d)\n", (ret == 0) ? "OK" : "FAILED", ret);

	if (ld2402_read_params(&params) == 0) {
		print_params(&params);
	}

	/* re-assert the output mode before leaving config mode */
	(void)ld2402_set_engineering_mode();

out_end_config:
	(void)ld2402_config_end();
	return ret == 0;
}

static void show_calib_result(bool ok)
{
	int64_t until = k_uptime_get() + CALIB_RESULT_SHOW_MS;

	/* keep sending so the display core does not report LINK: FAIL */
	while (k_uptime_get() < until) {
		send_calib_status(ok ? RADAR_CALIB_DONE : RADAR_CALIB_FAILED, 0);
		k_msleep(PERIODIC_SEND_MS);
	}
}

#if HAS_CALIB_BUTTON
static int64_t press_start_ms;
static bool press_handled;

static void calib_button_init(void)
{
	if (!gpio_is_ready_dt(&calib_button) ||
	    gpio_pin_configure_dt(&calib_button, GPIO_INPUT) != 0) {
		printk("[CALIB] button not available\n");
		return;
	}
	printk("[CALIB] hold the button %d s to run auto threshold\n",
	       CALIB_LONG_PRESS_MS / 1000);
}

/* Polled from the main loop (<= 500 ms period) - no ISR needed for a long press. */
static bool calib_long_press_detected(int64_t now)
{
	if (gpio_pin_get_dt(&calib_button) <= 0) {
		press_start_ms = 0;
		press_handled = false;
		return false;
	}
	if (press_start_ms == 0) {
		press_start_ms = now;
	}
	if (!press_handled && (now - press_start_ms) >= CALIB_LONG_PRESS_MS) {
		press_handled = true;
		return true;
	}
	return false;
}
#else
static void calib_button_init(void)
{
	printk("[CALIB] no calib-button alias - auto threshold disabled\n");
}

static bool calib_long_press_detected(int64_t now)
{
	ARG_UNUSED(now);
	return false;
}
#endif /* HAS_CALIB_BUTTON */

/* ------------------------------------------------------------------------ */
/* Radar message                                                             */
/* ------------------------------------------------------------------------ */

static void build_msg(struct radar_msg *msg, const struct ld2402_report *rep,
		      uint16_t filtered_cm, const struct radar_trend *trend, bool sensor_ok)
{
	memset(msg, 0, sizeof(*msg));
	msg->magic = RADAR_MSG_MAGIC;
	msg->uptime_ms = k_uptime_get_32();

	if (!sensor_ok) {
		return;
	}

	msg->flags |= RADAR_FLAG_SENSOR_OK;
	msg->presence = rep->presence;
	/* the radar keeps the last distance when the target is gone - clear it */
	msg->distance_cm = (rep->presence == LD2402_PRESENCE_NONE) ? 0 : filtered_cm;
	msg->direction = trend->direction;
	msg->speed_cms = trend->speed_cms;

	if (rep->has_energy) {
		msg->flags |= RADAR_FLAG_ENERGY;
		for (int i = 0; i < RADAR_GATE_COUNT; i++) {
			msg->motion_db[i] = ld2402_energy_to_db(rep->motion_energy[i]);
			msg->micro_db[i] = ld2402_energy_to_db(rep->micro_energy[i]);
		}
	}
}

static bool should_send(const struct radar_msg *now, const struct radar_msg *last,
			int64_t elapsed_ms)
{
	if (now->presence != last->presence || now->flags != last->flags ||
	    now->direction != last->direction) {
		return true;
	}
	if (abs((int)now->distance_cm - (int)last->distance_cm) >= DIST_DELTA_CM) {
		return true;
	}
	return elapsed_ms >= PERIODIC_SEND_MS;
}

static void log_status(const struct radar_msg *msg, uint16_t raw_cm)
{
	struct ld2402_stats st;
	int peak_gate = 0;

	for (int i = 1; i < RADAR_GATE_COUNT; i++) {
		if (msg->motion_db[i] > msg->motion_db[peak_gate]) {
			peak_gate = i;
		}
	}

	ld2402_get_stats(&st);
	printk("[SENSOR] %-5s dist=%3ucm (raw %3u) %-8s %+4dcm/s peak=%2udB@g%-2d"
	       " | sent=%u bin=%u txt=%u bad=%u ovf=%u%s\n",
	       presence_name(msg->presence), (unsigned int)msg->distance_cm,
	       (unsigned int)raw_cm, direction_name(msg->direction), (int)msg->speed_cms,
	       (unsigned int)msg->motion_db[peak_gate], peak_gate,
	       tx_seq, st.binary_frames, st.ascii_lines, st.bad_frames, st.rx_overflows,
	       (msg->flags & RADAR_FLAG_SENSOR_OK) ? "" : " [NO SENSOR]");
}

/* ------------------------------------------------------------------------ */
/* Main                                                                      */
/* ------------------------------------------------------------------------ */

int main(void)
{
	struct ld2402_report latest = {0};
	struct radar_msg last_sent = {0};
	struct radar_median median;
	struct radar_trend trend;
	uint16_t filtered_cm = 0;
	int64_t last_report_ms = -SENSOR_TIMEOUT_MS;
	int64_t last_send_ms = 0;
	int64_t last_log_ms = 0;

	printk("\n=== LD2402 AMP: sensor core (%s) ===\n", CONFIG_BOARD_TARGET);

	if (ld2402_init(radar_uart) != 0) {
		printk("[SENSOR] LD2402 UART not ready - check alias ld2402-uart\n");
		return 0;
	}
	if (radar_link_tx_init() != 0) {
		printk("[SENSOR] inter-core link init failed\n");
		return 0;
	}

	start_radar();
	calib_button_init();
	radar_median_reset(&median);
	radar_trend_reset(&trend);

	while (true) {
		struct ld2402_report rep;
		struct radar_msg msg;
		int64_t now;
		bool sensor_ok;

		if (ld2402_read_report(&rep, K_MSEC(REPORT_WAIT_MS)) == 0) {
			bool present = (rep.presence != LD2402_PRESENCE_NONE);

			latest = rep;
			last_report_ms = k_uptime_get();

			if (present) {
				filtered_cm = radar_median_update(&median, rep.distance_cm);
			} else {
				radar_median_reset(&median);
				filtered_cm = 0;
			}
			radar_trend_update(&trend, last_report_ms, filtered_cm, present);
		}

		now = k_uptime_get();

		if (calib_long_press_detected(now)) {
			bool ok = run_auto_threshold();

			show_calib_result(ok);
			radar_median_reset(&median);
			radar_trend_reset(&trend);
			last_report_ms = k_uptime_get(); /* grace period after config mode */
			continue;
		}

		sensor_ok = (now - last_report_ms) < SENSOR_TIMEOUT_MS;
		if (!sensor_ok) {
			radar_median_reset(&median);
			radar_trend_reset(&trend);
		}
		build_msg(&msg, &latest, filtered_cm, &trend, sensor_ok);

		if (should_send(&msg, &last_sent, now - last_send_ms)) {
			if (send_msg(&msg) == 0) {
				last_sent = msg;
				last_send_ms = now;
			}
		}

		if (now - last_log_ms >= LOG_PERIOD_MS) {
			log_status(&msg, latest.distance_cm);
			last_log_ms = now;
		}
	}

	return 0;
}
```
